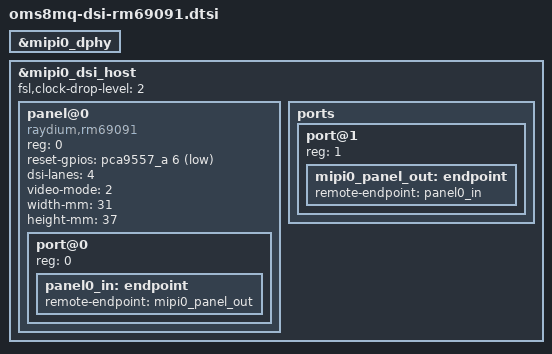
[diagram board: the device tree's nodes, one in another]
// SPDX-License-Identifier: GPL-2.0+
/*
 * Copyright 2023 Ocompany
 */

&mipi0_dphy {
	status = "okay";
};

&mipi0_dsi_host {
	status = "okay";
	fsl,clock-drop-level = <2>;

	panel@0 {
		#address-cells = <1>;
		#size-cells = <0>;

		compatible = "raydium,rm69091";
		reg = <0>;
		reset-gpios = <&pca9557_a 6 GPIO_ACTIVE_LOW>;
		dsi-lanes = <4>;
		video-mode = <2>;
		width-mm = <31>;
		height-mm = <37>;

		port@0 {
			reg = <0>;
			panel0_in: endpoint {
				remote-endpoint = <&mipi0_panel_out>;
			};
		};
	};

	ports {
		/delete-node/ port@1;

		port@1 {
			reg = <1>;
			mipi0_panel_out: endpoint {
				remote-endpoint = <&panel0_in>;
			};
		};
	};
};
